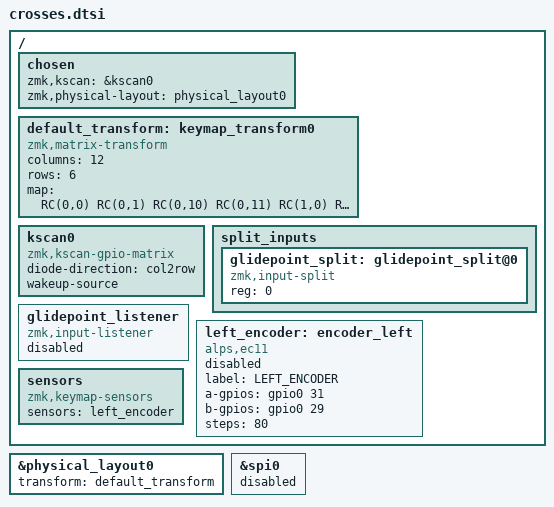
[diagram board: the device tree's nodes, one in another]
#include <dt-bindings/zmk/matrix_transform.h>
#include "crosses-layouts.dtsi"

&physical_layout0 {
  transform = <&default_transform>;
};

/{
    chosen {
        zmk,kscan = &kscan0;
        zmk,physical-layout = "physical_layout0";
    };

    default_transform: keymap_transform0 {
        compatible = "zmk,matrix-transform";
        columns = <12>;
        rows = <6>;
        map = <
RC(0,0)  RC(0,1)  RC(0,10) RC(0,11) RC(1,0)  RC(1,1)  RC(1,2)  RC(1,3)  RC(1,4)  RC(1,5) RC(1,6)  RC(1,7)  RC(1,8)  RC(1,9)  RC(1,10) RC(1,11) RC(2,0)  RC(2,1)  RC(2,2)  RC(2,3)  RC(2,4)  RC(2,5) RC(2,6)  RC(2,7)  RC(2,8)  RC(2,9)  RC(2,10) RC(2,11) RC(3,0)  RC(3,1)  RC(3,2)  RC(3,3)  RC(3,4)  RC(3,5) RC(3,6)  RC(3,7)  RC(3,8)  RC(3,9)  RC(3,10) RC(3,11) RC(4,0)  RC(4,1)  RC(4,2)  RC(4,3)  RC(4,4)  RC(4,5) RC(4,6)  RC(4,7)  RC(4,8)  RC(4,9)  RC(4,10) RC(4,11) RC(5,3)  RC(5,4)  RC(5,5) RC(5,6)  RC(5,7)  RC(5,8)>;
    };

    kscan0: kscan0 {
        compatible = "zmk,kscan-gpio-matrix";
        diode-direction = "col2row";
        wakeup-source;
    };

    split_inputs {
        #address-cells = <1>;
        #size-cells = <0>;
        glidepoint_split: glidepoint_split@0 {
            compatible = "zmk,input-split";
            reg = <0>;
        };
    };

    glidepoint_listener: glidepoint_listener {
        compatible = "zmk,input-listener";
        status = "disabled";
        //device = <&glidepoint_split>;
    };

left_encoder: encoder_left {
		compatible = "alps,ec11";
		label = "LEFT_ENCODER";
        a-gpios = <&gpio0 31 (GPIO_ACTIVE_HIGH | GPIO_PULL_UP)>;
        b-gpios = <&gpio0 29 (GPIO_ACTIVE_HIGH | GPIO_PULL_UP)>;
	steps = <80>;
		status = "disabled";
	};


    sensors {
		compatible = "zmk,keymap-sensors";
		sensors = <&left_encoder>;
	};

};

&spi0 {
    status = "disabled";
};
